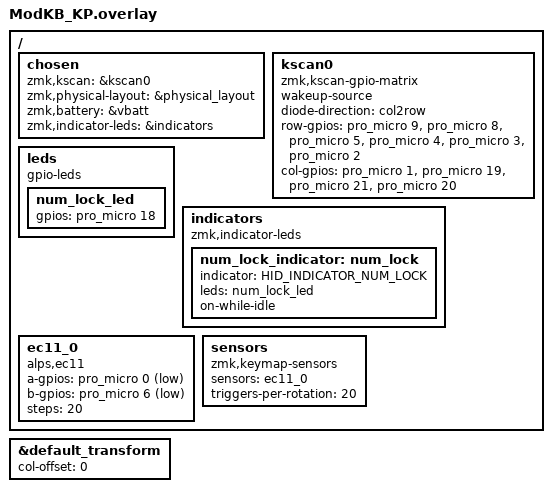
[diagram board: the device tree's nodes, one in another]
#include <dt-bindings/zmk/matrix_transform.h>
#include <dt-bindings/zmk/hid_indicators.h>
#include "ModKB.dtsi"


//transform

    &default_transform {
        col-offset = <0>;
    };


/ {
//chosen
    chosen {
        zmk,kscan = &kscan0;
        zmk,physical-layout = &physical_layout;
        zmk,battery = &vbatt;
        zmk,indicator-leds = &indicators;
    };


//kscan
    // PIN MAPPING KEYPAD

    kscan0: kscan0 { 
        compatible = "zmk,kscan-gpio-matrix";
        wakeup-source;
        diode-direction = "col2row";

        row-gpios
            = <&pro_micro 9 (GPIO_ACTIVE_HIGH | GPIO_PULL_DOWN) > // row 31
            , <&pro_micro 8 (GPIO_ACTIVE_HIGH | GPIO_PULL_DOWN) > // row 32
            , <&pro_micro 5 (GPIO_ACTIVE_HIGH | GPIO_PULL_DOWN) > // row 33
            , <&pro_micro 4 (GPIO_ACTIVE_HIGH | GPIO_PULL_DOWN) > // row 34
            , <&pro_micro 3 (GPIO_ACTIVE_HIGH | GPIO_PULL_DOWN) > // row 35
            , <&pro_micro 2 (GPIO_ACTIVE_HIGH | GPIO_PULL_DOWN) > // row 36

            ;
        col-gpios 
            = <&pro_micro 1 GPIO_ACTIVE_HIGH > // column 31
            , <&pro_micro 19 GPIO_ACTIVE_HIGH > // column 32
            , <&pro_micro 21 GPIO_ACTIVE_HIGH > // column 33
            , <&pro_micro 20 GPIO_ACTIVE_HIGH > // column 34
            ;
    };


// led and indicators, only work on central
// so leds are defined in LH

//led and idicators
    // development verison, cant use the library in 0.3V
    leds {
        compatible = "gpio-leds";

        num_lock_led: num_lock_led {
            gpios = <&pro_micro 18 GPIO_ACTIVE_HIGH>;
        };
    };

    indicators: indicators {
            compatible = "zmk,indicator-leds";

            num_lock_indicator: num_lock {
                indicator = <HID_INDICATOR_NUM_LOCK>;
                leds = <&num_lock_led>;
                on-while-idle;
            };
    };

// EC11

    ec11_0: ec11_0 {
        compatible = "alps,ec11";
        a-gpios = <&pro_micro 0 (GPIO_ACTIVE_LOW | GPIO_PULL_UP)>;
        b-gpios = <&pro_micro 6 (GPIO_ACTIVE_LOW | GPIO_PULL_UP)>;
        steps = <20>; //Number of encoder pulses per complete rotation
        status = "okay";
    };
 //(GPIO_ACTIVE_HIGH | GPIO_PULL_DOWN)
 //(GPIO_ACTIVE_LOW | GPIO_PULL_UP)
   sensors: sensors {
        compatible = "zmk,keymap-sensors";
        sensors = <&ec11_0>;
        triggers-per-rotation = <20>;
    };

};


/*

        num_lock_led: num_lock{
            gpios = <&gpio0 21 GPIO_ACTIVE_HIGH>;
        };

            num_lock_indicator: num_lock {
                indicator = <HID_INDICATOR_NUM_LOCK>;
                leds = <&num_lock_led>;
                on-while-idle;
            };
*/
